AUTOSAR XML (schema 4-2-2)
package /Components
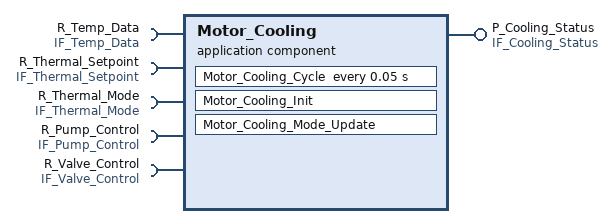
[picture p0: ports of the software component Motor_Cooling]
  application sw component type Motor_Cooling
    provide port P_Cooling_Status: provided-interface=IF_Cooling_Status
    5 x require port:
      R_Temp_Data: required-interface=IF_Temp_Data
      R_Thermal_Setpoint: required-interface=IF_Thermal_Setpoint
      R_Thermal_Mode: required-interface=IF_Thermal_Mode
      R_Pump_Control: required-interface=IF_Pump_Control
      R_Valve_Control: required-interface=IF_Valve_Control
    behavior Motor_Cooling_InternalBehavior
      data received event Motor_Cooling_Setpoint_Update: start-on-event=Motor_Cooling_Cycle
      init event Motor_Cooling_Init_Event: start-on-event=Motor_Cooling_Init
      swc mode switch event Motor_Cooling_Mode_Switch: start-on-event=Motor_Cooling_Mode_Update, activation=ON-TRANSITION, mode=ThermalModeGroup.R_Thermal_Mode.Performance
      timing event Motor_Cooling_Periodic_50ms: start-on-event=Motor_Cooling_Cycle, period=0.05
      runnable Motor_Cooling_Init: mode-access-point=R_Thermal_Mode.ThermalModeGroup
        data-read-access:
          access VA_Read_t_motor_Init: accessed-variable=R_Temp_Data.t_motor
        data-receive-point-by-values:
          access VA_Rcv_TargetMotorFlow_Init: accessed-variable=R_Thermal_Setpoint.target_motor_coolant_flow
        data-send-points:
          access VA_Send_MotorStatus_Init: accessed-variable=P_Cooling_Status.motor_cooling_status
        data-write-access:
          access VA_Write_MotorStatus_Init: accessed-variable=P_Cooling_Status.motor_cooling_status
        sync call SCP_GetPumpStatus_Init: operation=R_Pump_Control.op_get_pump_status, timeout=50
      runnable Motor_Cooling_Cycle: minimum-start-interval=0.05, mode-access-point=R_Thermal_Mode.ThermalModeGroup
        data-read-access:
          access VA_Read_t_motor_Cycle: accessed-variable=R_Temp_Data.t_motor
          access VA_Read_TargetMotorFlow_Cycle: accessed-variable=R_Thermal_Setpoint.target_motor_coolant_flow
        data-receive-point-by-values:
          access VA_Rcv_TargetMotorFlow_Cycle: accessed-variable=R_Thermal_Setpoint.target_motor_coolant_flow
        data-send-points:
          access VA_Send_MotorStatus_Cycle: accessed-variable=P_Cooling_Status.motor_cooling_status
        data-write-access:
          access VA_Write_MotorStatus_Cycle: accessed-variable=P_Cooling_Status.motor_cooling_status
        sync call SCP_SetPumpSpeed_Cycle: operation=R_Pump_Control.op_set_pump_speed, timeout=50
        sync call SCP_SetValvePosition_Cycle: operation=R_Valve_Control.op_set_valve_position, timeout=50
      runnable Motor_Cooling_Mode_Update: mode-access-point=R_Thermal_Mode.ThermalModeGroup
        data-read-access:
          access VA_Read_t_inverter_Mode: accessed-variable=R_Temp_Data.t_inverter
        data-receive-point-by-values:
          access VA_Rcv_TargetMotorFlow_Mode: accessed-variable=R_Thermal_Setpoint.target_motor_coolant_flow
        data-send-points:
          access VA_Send_MotorStatus_Mode: accessed-variable=P_Cooling_Status.motor_cooling_status
        data-write-access:
          access VA_Write_MotorStatus_Mode: accessed-variable=P_Cooling_Status.motor_cooling_status
        sync call SCP_GetValveStatus_Mode: operation=R_Valve_Control.op_get_valve_status, timeout=50
